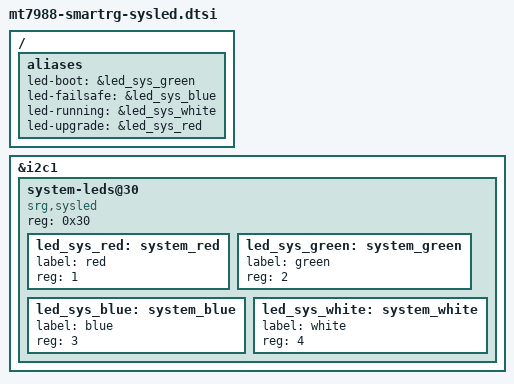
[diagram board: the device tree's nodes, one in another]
// SPDX-License-Identifier: (GPL-2.0 OR MIT)
/*
 * Copyright (C) 2026 SmartRG Inc.
 * Author: Chad Monroe <chad.monroe@smartrg.com>
 *
 * Holtek MCU system LED controller on i2c1. SDG-9000 has its own
 * controller on i2c2 and does not include this file.
 */

/ {
	aliases {
		led-boot = &led_sys_green;
		led-failsafe = &led_sys_blue;
		led-running = &led_sys_white;
		led-upgrade = &led_sys_red;
	};
};

&i2c1 {
	system-leds@30 {
		compatible = "srg,sysled";
		reg = <0x30>;
		#address-cells = <1>;
		#size-cells = <0>;

		led_sys_red: system_red {
			label = "red";
			reg = <1>;
		};

		led_sys_green: system_green {
			label = "green";
			reg = <2>;
		};

		led_sys_blue: system_blue {
			label = "blue";
			reg = <3>;
		};

		led_sys_white: system_white {
			label = "white";
			reg = <4>;
		};
	};
};
